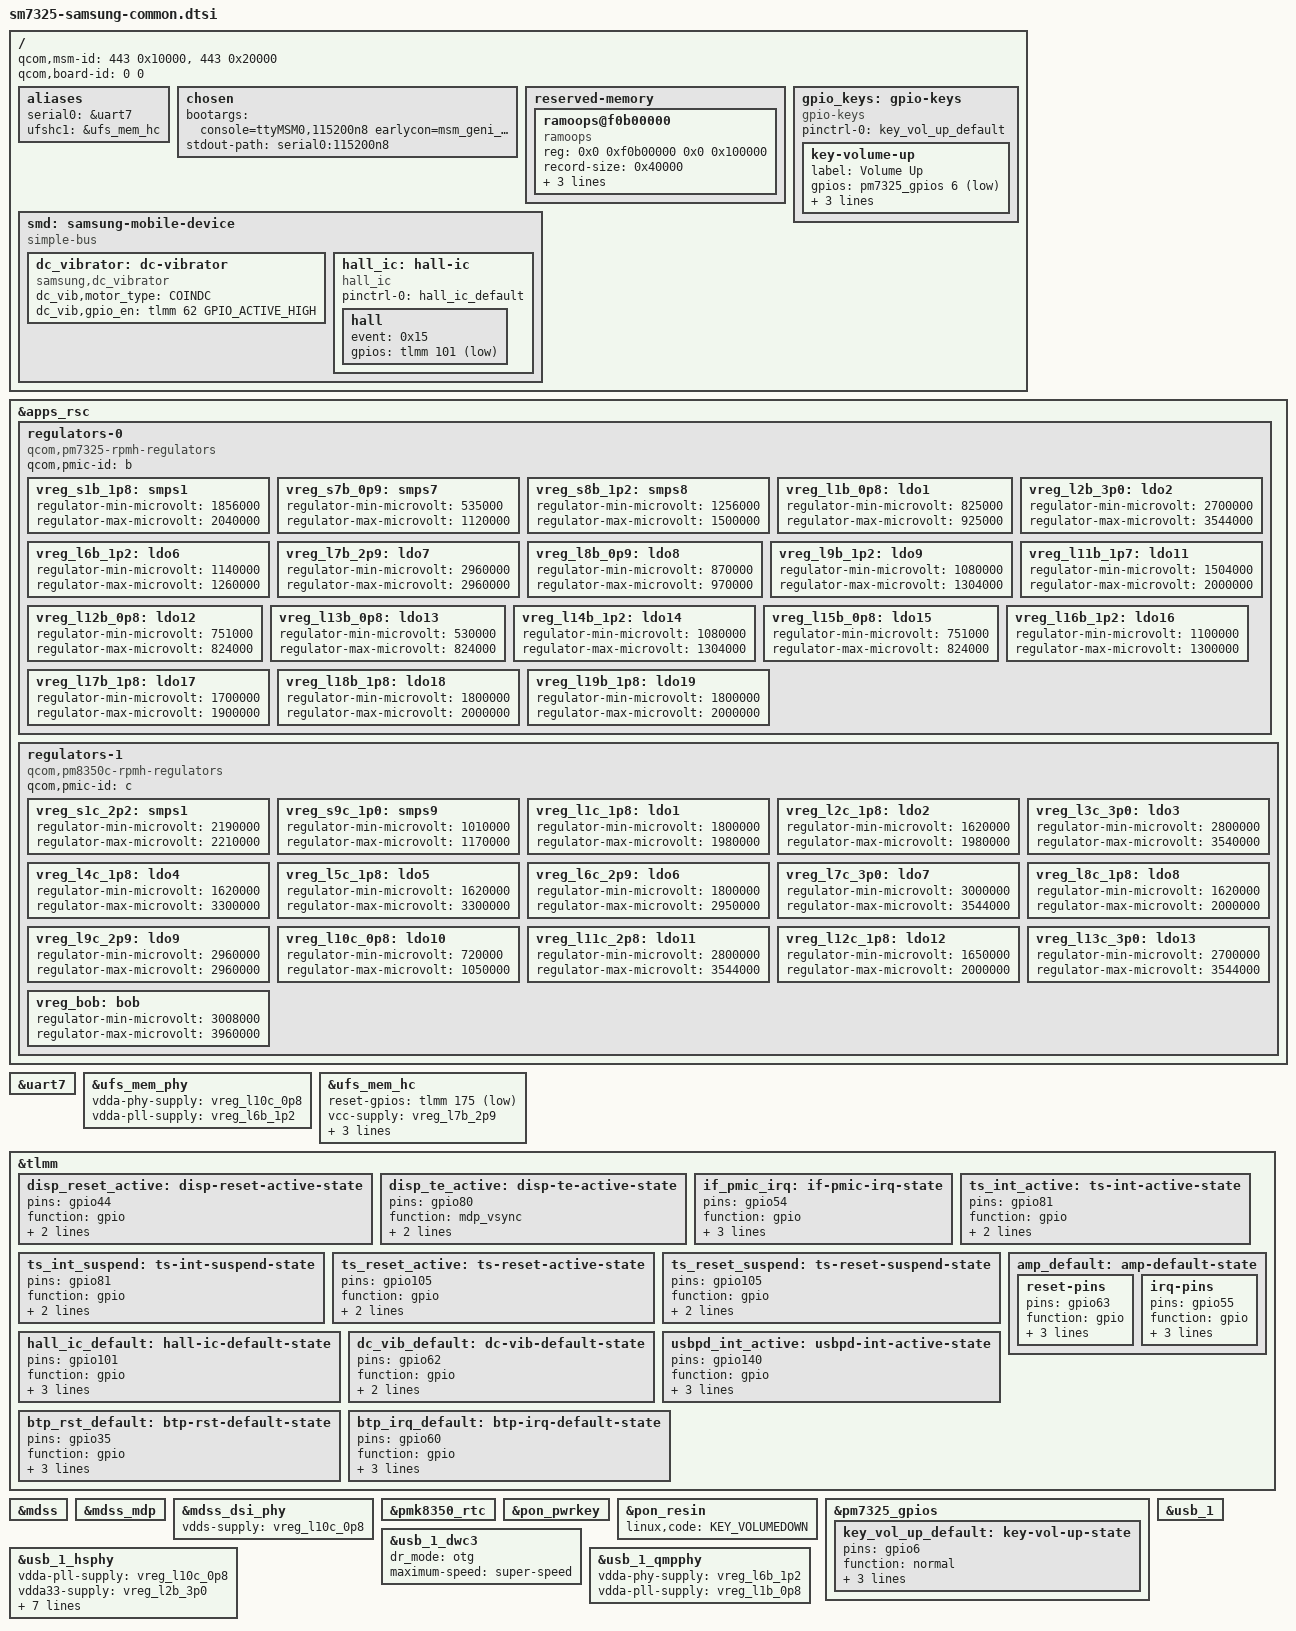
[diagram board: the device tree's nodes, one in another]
// SPDX-License-Identifier: BSD-3-Clause
/*
 * Copyright (c) 2021, The Linux Foundation. All rights reserved.
 * Copyright (c) 2026, Jiro <ktgithub28@gmail.com>
 *
 * Common Device Tree include for Samsung SM7325 (Yupik) devices
 */

#include <dt-bindings/input/input.h>
#include <dt-bindings/input/linux-event-codes.h>
#include "sm7325.dtsi"
#include "pmk8350.dtsi"
#include "pm7325.dtsi"
#include "pm8350.dtsi"
#include "pm8350b.dtsi"
#include "pm8350c.dtsi"

/ {
	qcom,msm-id = <443 0x10000>, <443 0x20000>;
	qcom,board-id = <0 0>;

	aliases {
		serial0 = &uart7;
		ufshc1 = &ufs_mem_hc;
	};

	chosen {
		bootargs = "console=ttyMSM0,115200n8 earlycon=msm_geni_serial,0x99c000";
		stdout-path = "serial0:115200n8";
	};

	reserved-memory {
		#address-cells = <2>;
		#size-cells = <2>;
		ranges;

		/* Samsung SBOOT persistent RAM oops/panic logger */
		ramoops@f0b00000 {
			compatible = "ramoops";
			reg = <0x0 0xf0b00000 0x0 0x100000>;
			record-size = <0x40000>;
			console-size = <0x40000>;
			ftrace-size = <0x40000>;
			pmsg-size = <0x40000>;
		};
	};

	gpio_keys: gpio-keys {
		compatible = "gpio-keys";
		pinctrl-names = "default";
		pinctrl-0 = <&key_vol_up_default>;

		key-volume-up {
			label = "Volume Up";
			gpios = <&pm7325_gpios 6 GPIO_ACTIVE_LOW>;
			linux,code = <KEY_VOLUMEUP>;
			debounce-interval = <15>;
			wakeup-source;
		};
	};

	smd: samsung-mobile-device {
		compatible = "simple-bus";
		#address-cells = <1>;
		#size-cells = <0>;

		dc_vibrator: dc-vibrator {
			compatible = "samsung,dc_vibrator";
			status = "okay";
			dc_vib,motor_type = "COINDC";
			dc_vib,gpio_en = <&tlmm 62 GPIO_ACTIVE_HIGH>;
		};

		hall_ic: hall-ic {
			compatible = "hall_ic";
			status = "okay";
			pinctrl-names = "default";
			pinctrl-0 = <&hall_ic_default>;

			hall {
				event = <0x15>;
				gpios = <&tlmm 101 GPIO_ACTIVE_LOW>;
			};
		};
	};
};

&apps_rsc {
	regulators-0 {
		compatible = "qcom,pm7325-rpmh-regulators";
		qcom,pmic-id = "b";

		vreg_s1b_1p8: smps1 {
			regulator-min-microvolt = <1856000>;
			regulator-max-microvolt = <2040000>;
		};

		vreg_s7b_0p9: smps7 {
			regulator-min-microvolt = <535000>;
			regulator-max-microvolt = <1120000>;
		};

		vreg_s8b_1p2: smps8 {
			regulator-min-microvolt = <1256000>;
			regulator-max-microvolt = <1500000>;
		};

		vreg_l1b_0p8: ldo1 {
			regulator-min-microvolt = <825000>;
			regulator-max-microvolt = <925000>;
		};

		vreg_l2b_3p0: ldo2 {
			regulator-min-microvolt = <2700000>;
			regulator-max-microvolt = <3544000>;
		};

		vreg_l6b_1p2: ldo6 {
			regulator-min-microvolt = <1140000>;
			regulator-max-microvolt = <1260000>;
		};

		vreg_l7b_2p9: ldo7 {
			regulator-min-microvolt = <2960000>;
			regulator-max-microvolt = <2960000>;
		};

		vreg_l8b_0p9: ldo8 {
			regulator-min-microvolt = <870000>;
			regulator-max-microvolt = <970000>;
		};

		vreg_l9b_1p2: ldo9 {
			regulator-min-microvolt = <1080000>;
			regulator-max-microvolt = <1304000>;
		};

		vreg_l11b_1p7: ldo11 {
			regulator-min-microvolt = <1504000>;
			regulator-max-microvolt = <2000000>;
		};

		vreg_l12b_0p8: ldo12 {
			regulator-min-microvolt = <751000>;
			regulator-max-microvolt = <824000>;
		};

		vreg_l13b_0p8: ldo13 {
			regulator-min-microvolt = <530000>;
			regulator-max-microvolt = <824000>;
		};

		vreg_l14b_1p2: ldo14 {
			regulator-min-microvolt = <1080000>;
			regulator-max-microvolt = <1304000>;
		};

		vreg_l15b_0p8: ldo15 {
			regulator-min-microvolt = <751000>;
			regulator-max-microvolt = <824000>;
		};

		vreg_l16b_1p2: ldo16 {
			regulator-min-microvolt = <1100000>;
			regulator-max-microvolt = <1300000>;
		};

		vreg_l17b_1p8: ldo17 {
			regulator-min-microvolt = <1700000>;
			regulator-max-microvolt = <1900000>;
		};

		vreg_l18b_1p8: ldo18 {
			regulator-min-microvolt = <1800000>;
			regulator-max-microvolt = <2000000>;
		};

		vreg_l19b_1p8: ldo19 {
			regulator-min-microvolt = <1800000>;
			regulator-max-microvolt = <2000000>;
		};
	};

	regulators-1 {
		compatible = "qcom,pm8350c-rpmh-regulators";
		qcom,pmic-id = "c";

		vreg_s1c_2p2: smps1 {
			regulator-min-microvolt = <2190000>;
			regulator-max-microvolt = <2210000>;
		};

		vreg_s9c_1p0: smps9 {
			regulator-min-microvolt = <1010000>;
			regulator-max-microvolt = <1170000>;
		};

		vreg_l1c_1p8: ldo1 {
			regulator-min-microvolt = <1800000>;
			regulator-max-microvolt = <1980000>;
		};

		vreg_l2c_1p8: ldo2 {
			regulator-min-microvolt = <1620000>;
			regulator-max-microvolt = <1980000>;
		};

		vreg_l3c_3p0: ldo3 {
			regulator-min-microvolt = <2800000>;
			regulator-max-microvolt = <3540000>;
		};

		vreg_l4c_1p8: ldo4 {
			regulator-min-microvolt = <1620000>;
			regulator-max-microvolt = <3300000>;
		};

		vreg_l5c_1p8: ldo5 {
			regulator-min-microvolt = <1620000>;
			regulator-max-microvolt = <3300000>;
		};

		vreg_l6c_2p9: ldo6 {
			regulator-min-microvolt = <1800000>;
			regulator-max-microvolt = <2950000>;
		};

		vreg_l7c_3p0: ldo7 {
			regulator-min-microvolt = <3000000>;
			regulator-max-microvolt = <3544000>;
		};

		vreg_l8c_1p8: ldo8 {
			regulator-min-microvolt = <1620000>;
			regulator-max-microvolt = <2000000>;
		};

		vreg_l9c_2p9: ldo9 {
			regulator-min-microvolt = <2960000>;
			regulator-max-microvolt = <2960000>;
		};

		vreg_l10c_0p8: ldo10 {
			regulator-min-microvolt = <720000>;
			regulator-max-microvolt = <1050000>;
		};

		vreg_l11c_2p8: ldo11 {
			regulator-min-microvolt = <2800000>;
			regulator-max-microvolt = <3544000>;
		};

		vreg_l12c_1p8: ldo12 {
			regulator-min-microvolt = <1650000>;
			regulator-max-microvolt = <2000000>;
		};

		vreg_l13c_3p0: ldo13 {
			regulator-min-microvolt = <2700000>;
			regulator-max-microvolt = <3544000>;
		};

		vreg_bob: bob {
			regulator-min-microvolt = <3008000>;
			regulator-max-microvolt = <3960000>;
		};
	};
};

&uart7 {
	status = "okay";
};

&ufs_mem_phy {
	status = "okay";
	vdda-phy-supply = <&vreg_l10c_0p8>;
	vdda-pll-supply = <&vreg_l6b_1p2>;
};

&ufs_mem_hc {
	status = "okay";
	reset-gpios = <&tlmm 175 GPIO_ACTIVE_LOW>;
	vcc-supply = <&vreg_l7b_2p9>;
	vcc-max-microamp = <800000>;
	vccq-supply = <&vreg_l9b_1p2>;
	vccq-max-microamp = <900000>;
};

&tlmm {
	disp_reset_active: disp-reset-active-state {
		pins = "gpio44";
		function = "gpio";
		drive-strength = <8>;
		bias-disable;
	};

	disp_te_active: disp-te-active-state {
		pins = "gpio80";
		function = "mdp_vsync";
		drive-strength = <2>;
		bias-pull-down;
	};

	if_pmic_irq: if-pmic-irq-state {
		pins = "gpio54";
		function = "gpio";
		drive-strength = <2>;
		input-enable;
		bias-disable;
	};

	ts_int_active: ts-int-active-state {
		pins = "gpio81";
		function = "gpio";
		input-enable;
		bias-disable;
	};

	ts_int_suspend: ts-int-suspend-state {
		pins = "gpio81";
		function = "gpio";
		input-enable;
		bias-pull-down;
	};

	ts_reset_active: ts-reset-active-state {
		pins = "gpio105";
		function = "gpio";
		drive-strength = <2>;
		bias-disable;
	};

	ts_reset_suspend: ts-reset-suspend-state {
		pins = "gpio105";
		function = "gpio";
		drive-strength = <2>;
		bias-pull-down;
	};

	hall_ic_default: hall-ic-default-state {
		pins = "gpio101";
		function = "gpio";
		drive-strength = <2>;
		bias-pull-up;
		input-enable;
	};

	dc_vib_default: dc-vib-default-state {
		pins = "gpio62";
		function = "gpio";
		drive-strength = <8>;
		output-low;
	};

	usbpd_int_active: usbpd-int-active-state {
		pins = "gpio140";
		function = "gpio";
		drive-strength = <2>;
		bias-pull-up;
		input-enable;
	};

	btp_rst_default: btp-rst-default-state {
		pins = "gpio35";
		function = "gpio";
		drive-strength = <2>;
		output-low;
		bias-pull-down;
	};

	btp_irq_default: btp-irq-default-state {
		pins = "gpio60";
		function = "gpio";
		drive-strength = <6>;
		input-enable;
		bias-pull-down;
	};

	amp_default: amp-default-state {
		reset-pins {
			pins = "gpio63";
			function = "gpio";
			drive-strength = <2>;
			bias-disable;
			output-low;
		};

		irq-pins {
			pins = "gpio55";
			function = "gpio";
			drive-strength = <2>;
			bias-pull-up;
			input-enable;
		};
	};
};

&mdss {
	status = "okay";
};

&mdss_mdp {
	status = "okay";
};

&mdss_dsi_phy {
	status = "okay";
	vdds-supply = <&vreg_l10c_0p8>;
};

&pmk8350_rtc {
	status = "okay";
};

&pon_pwrkey {
	status = "okay";
};

&pon_resin {
	status = "okay";
	linux,code = <KEY_VOLUMEDOWN>;
};

&pm7325_gpios {
	key_vol_up_default: key-vol-up-state {
		pins = "gpio6";
		function = "normal";
		input-enable;
		bias-pull-up;
		power-source = <0>;
	};
};

&usb_1 {
	status = "okay";
};

&usb_1_dwc3 {
	dr_mode = "otg";
	maximum-speed = "super-speed";
};

&usb_1_hsphy {
	status = "okay";
	vdda-pll-supply = <&vreg_l10c_0p8>;
	vdda33-supply = <&vreg_l2b_3p0>;
	vdda18-supply = <&vreg_l1c_1p8>;
	qcom,hs-rise-fall-time-bp = <0>;
	qcom,squelch-detector-bp = <(-2090)>;
	qcom,hs-disconnect-bp = <1743>;
	qcom,hs-amplitude-bp = <1780>;
	qcom,hs-crossover-voltage-microvolt = <(-31000)>;
	qcom,hs-output-impedance-micro-ohms = <2600000>;
};

&usb_1_qmpphy {
	status = "okay";
	vdda-phy-supply = <&vreg_l6b_1p2>;
	vdda-pll-supply = <&vreg_l1b_0p8>;
};
